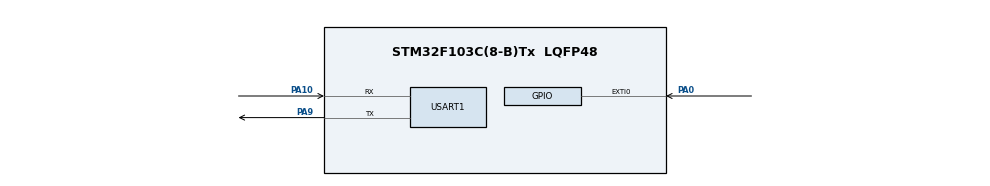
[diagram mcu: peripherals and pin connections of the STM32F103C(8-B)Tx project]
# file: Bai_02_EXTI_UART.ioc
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FREERTOS.Tasks01=defaultTask,0,128,StartDefaultTask,Default,NULL,Dynamic,NULL,NULL
FREERTOS.configTOTAL_HEAP_SIZE=8192
Mcu.Family=STM32F1
Mcu.Name=STM32F103C(8-B)Tx
Mcu.Package=LQFP48
NVIC.EXTI0_IRQn=true\:5\:0\:true\:false\:true\:true\:true\:true\:true
NVIC.PriorityGroup=NVIC_PRIORITYGROUP_4
NVIC.TIM4_IRQn=true\:15\:0\:false\:false\:true\:false\:false\:true\:true
NVIC.TimeBase=TIM4_IRQn
NVIC.TimeBaseIP=TIM4
PA0-WKUP.GPIO_ModeDefaultEXTI=GPIO_MODE_IT_FALLING
PA0-WKUP.GPIO_PuPd=GPIO_PULLUP
PA0-WKUP.Signal=GPXTI0
PA10.Mode=Asynchronous
PA10.Signal=USART1_RX
PA13.Mode=Serial_Wire
PA13.Signal=SYS_JTMS-SWDIO
PA14.Mode=Serial_Wire
PA14.Signal=SYS_JTCK-SWCLK
PA9.Mode=Asynchronous
PA9.Signal=USART1_TX
PD0-OSC_IN.Mode=HSE-External-Oscillator
PD0-OSC_IN.Signal=RCC_OSC_IN
PD1-OSC_OUT.Mode=HSE-External-Oscillator
PD1-OSC_OUT.Signal=RCC_OSC_OUT
ProjectManager.HeapSize=0x200
ProjectManager.StackSize=0x400
ProjectManager.TargetToolchain=MDK-ARM V5.32
RCC.APB1Freq_Value=8000000
RCC.APB2Freq_Value=8000000
RCC.PLLMUL=RCC_PLL_MUL9
RCC.USBFreq_Value=36000000
USART1.VirtualMode=VM_ASYNC
VP_FREERTOS_VS_CMSIS_V1.Mode=CMSIS_V1
VP_SYS_VS_tim4.Mode=TIM4
board=custom

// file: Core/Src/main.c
/* USER CODE BEGIN Header */
/**
  * Bai tap 02: STM32F103C8 + FreeRTOS (CMSIS_V1)
  * - PA0: EXTI0, canh xuong (nut nhan noi PA0 -> GND)
  * - ISR: tang bien dem, xQueueSendFromISR, portYIELD_FROM_ISR
  * - Task UART: Blocked cho Queue, dinh dang chuoi, gui qua USART1 (PA9/PA10)
  * - Timebase HAL: TIM4 (SysTick danh cho FreeRTOS)
  */
/* USER CODE END Header */
#include "main.h"
#include "cmsis_os.h"

/* USER CODE BEGIN Includes */
#include "FreeRTOS.h"
#include "task.h"
#include "queue.h"
#include <stdio.h>
#include <string.h>
/* USER CODE END Includes */

UART_HandleTypeDef huart1;

osThreadId defaultTaskHandle;
/* USER CODE BEGIN PV */
QueueHandle_t xCountQueue = NULL;
volatile uint32_t pressCount = 0;
/* USER CODE END PV */

void SystemClock_Config(void);
static void MX_GPIO_Init(void);
static void MX_USART1_UART_Init(void);
void StartDefaultTask(void const * argument);

/* USER CODE BEGIN PFP */
void vUartTask(void *pvParameters);
/* USER CODE END PFP */

int main(void)
{

  /* MCU Configuration--------------------------------------------------------*/

  /* Reset of all peripherals, Initializes the Flash interface and the Systick. */
  HAL_Init();

  /* Configure the system clock */
  SystemClock_Config();

  /* Initialize all configured peripherals */
  MX_GPIO_Init();
  MX_USART1_UART_Init();
  /* USER CODE BEGIN 2 */
  xCountQueue = xQueueCreate(8, sizeof(uint32_t));
  xTaskCreate(vUartTask, "UartTask", 256, NULL, 2, NULL);
  /* USER CODE END 2 */

  /* Create the thread(s) */
  /* definition and creation of defaultTask */
  osThreadDef(defaultTask, StartDefaultTask, osPriorityNormal, 0, 128);
  defaultTaskHandle = osThreadCreate(osThread(defaultTask), NULL);

  /* Start scheduler */
  osKernelStart();

  /* We should never get here as control is now taken by the scheduler */

  /* Infinite loop */
  while (1)
  {

  }
}

void SystemClock_Config(void)
{
  RCC_OscInitTypeDef RCC_OscInitStruct = {0};
  RCC_ClkInitTypeDef RCC_ClkInitStruct = {0};

  /** Initializes the RCC Oscillators according to the specified parameters
  * in the RCC_OscInitTypeDef structure.
  */
  RCC_OscInitStruct.OscillatorType = RCC_OSCILLATORTYPE_HSI;
  RCC_OscInitStruct.HSIState = RCC_HSI_ON;
  RCC_OscInitStruct.HSICalibrationValue = RCC_HSICALIBRATION_DEFAULT;
  RCC_OscInitStruct.PLL.PLLState = RCC_PLL_NONE;
  if (HAL_RCC_OscConfig(&RCC_OscInitStruct) != HAL_OK)
  {
    Error_Handler();
  }

  /** Initializes the CPU, AHB and APB buses clocks
  */
  RCC_ClkInitStruct.ClockType = RCC_CLOCKTYPE_HCLK|RCC_CLOCKTYPE_SYSCLK
                              |RCC_CLOCKTYPE_PCLK1|RCC_CLOCKTYPE_PCLK2;
  RCC_ClkInitStruct.SYSCLKSource = RCC_SYSCLKSOURCE_HSI;
  RCC_ClkInitStruct.AHBCLKDivider = RCC_SYSCLK_DIV1;
  RCC_ClkInitStruct.APB1CLKDivider = RCC_HCLK_DIV1;
  RCC_ClkInitStruct.APB2CLKDivider = RCC_HCLK_DIV1;

  if (HAL_RCC_ClockConfig(&RCC_ClkInitStruct, FLASH_LATENCY_0) != HAL_OK)
  {
    Error_Handler();
  }
}

static void MX_USART1_UART_Init(void)
{

  huart1.Instance = USART1;
  huart1.Init.BaudRate = 115200;
  huart1.Init.WordLength = UART_WORDLENGTH_8B;
  huart1.Init.StopBits = UART_STOPBITS_1;
  huart1.Init.Parity = UART_PARITY_NONE;
  huart1.Init.Mode = UART_MODE_TX_RX;
  huart1.Init.HwFlowCtl = UART_HWCONTROL_NONE;
  huart1.Init.OverSampling = UART_OVERSAMPLING_16;
  if (HAL_UART_Init(&huart1) != HAL_OK)
  {
    Error_Handler();
  }

}

static void MX_GPIO_Init(void)
{
  GPIO_InitTypeDef GPIO_InitStruct = {0};

  /* GPIO Ports Clock Enable */
  __HAL_RCC_GPIOD_CLK_ENABLE();
  __HAL_RCC_GPIOA_CLK_ENABLE();

  /*Configure GPIO pin : PA0 */
  GPIO_InitStruct.Pin = GPIO_PIN_0;
  GPIO_InitStruct.Mode = GPIO_MODE_IT_FALLING;
  GPIO_InitStruct.Pull = GPIO_PULLUP;
  HAL_GPIO_Init(GPIOA, &GPIO_InitStruct);

  /* EXTI interrupt init*/
  HAL_NVIC_SetPriority(EXTI0_IRQn, 5, 0);
  HAL_NVIC_EnableIRQ(EXTI0_IRQn);

}

/* USER CODE BEGIN 4 */

/* HAL goi ham nay tu EXTI0_IRQHandler */
void HAL_GPIO_EXTI_Callback(uint16_t GPIO_Pin)
{
  static TickType_t lastTick = 0;
  BaseType_t xHigherPriorityTaskWoken = pdFALSE;

  if (GPIO_Pin == GPIO_PIN_0 && xCountQueue != NULL)
  {
    TickType_t now = xTaskGetTickCountFromISR();

    /* Chong doi phim 200 ms */
    if ((now - lastTick) >= pdMS_TO_TICKS(200))
    {
      lastTick = now;
      pressCount++;                                         /* 1. Tang bien dem */
      xQueueSendFromISR(xCountQueue, (const void *)&pressCount,
                        &xHigherPriorityTaskWoken);         /* 2. Gui vao Queue */
    }
  }
  portYIELD_FROM_ISR(xHigherPriorityTaskWoken);             /* 3. Chuyen ngu canh ngay */
}

void vUartTask(void *pvParameters)
{
  uint32_t rxCount;
  char buf[48];

  const char *hello = "=== STM32F103 FreeRTOS EXTI + UART ===\r\n";
  HAL_UART_Transmit(&huart1, (uint8_t *)hello, strlen(hello), 100);

  for (;;)
  {
    /* Blocked vo thoi han den khi co du lieu trong Queue */
    if (xQueueReceive(xCountQueue, &rxCount, portMAX_DELAY) == pdPASS)
    {
      int len = snprintf(buf, sizeof(buf),
                         "Nut nhan duoc nhan: %lu lan\r\n",
                         (unsigned long)rxCount);
      HAL_UART_Transmit(&huart1, (uint8_t *)buf, len, 100);
    }
  }
}

/* USER CODE END 4 */

void StartDefaultTask(void const * argument)
{
  for(;;)
  {
    osDelay(1);
  }
}

void HAL_TIM_PeriodElapsedCallback(TIM_HandleTypeDef *htim)
{
  if (htim->Instance == TIM4)
  {
    HAL_IncTick();
  }
}

void Error_Handler(void)
{
  __disable_irq();
  while (1)
  {
  }
}
